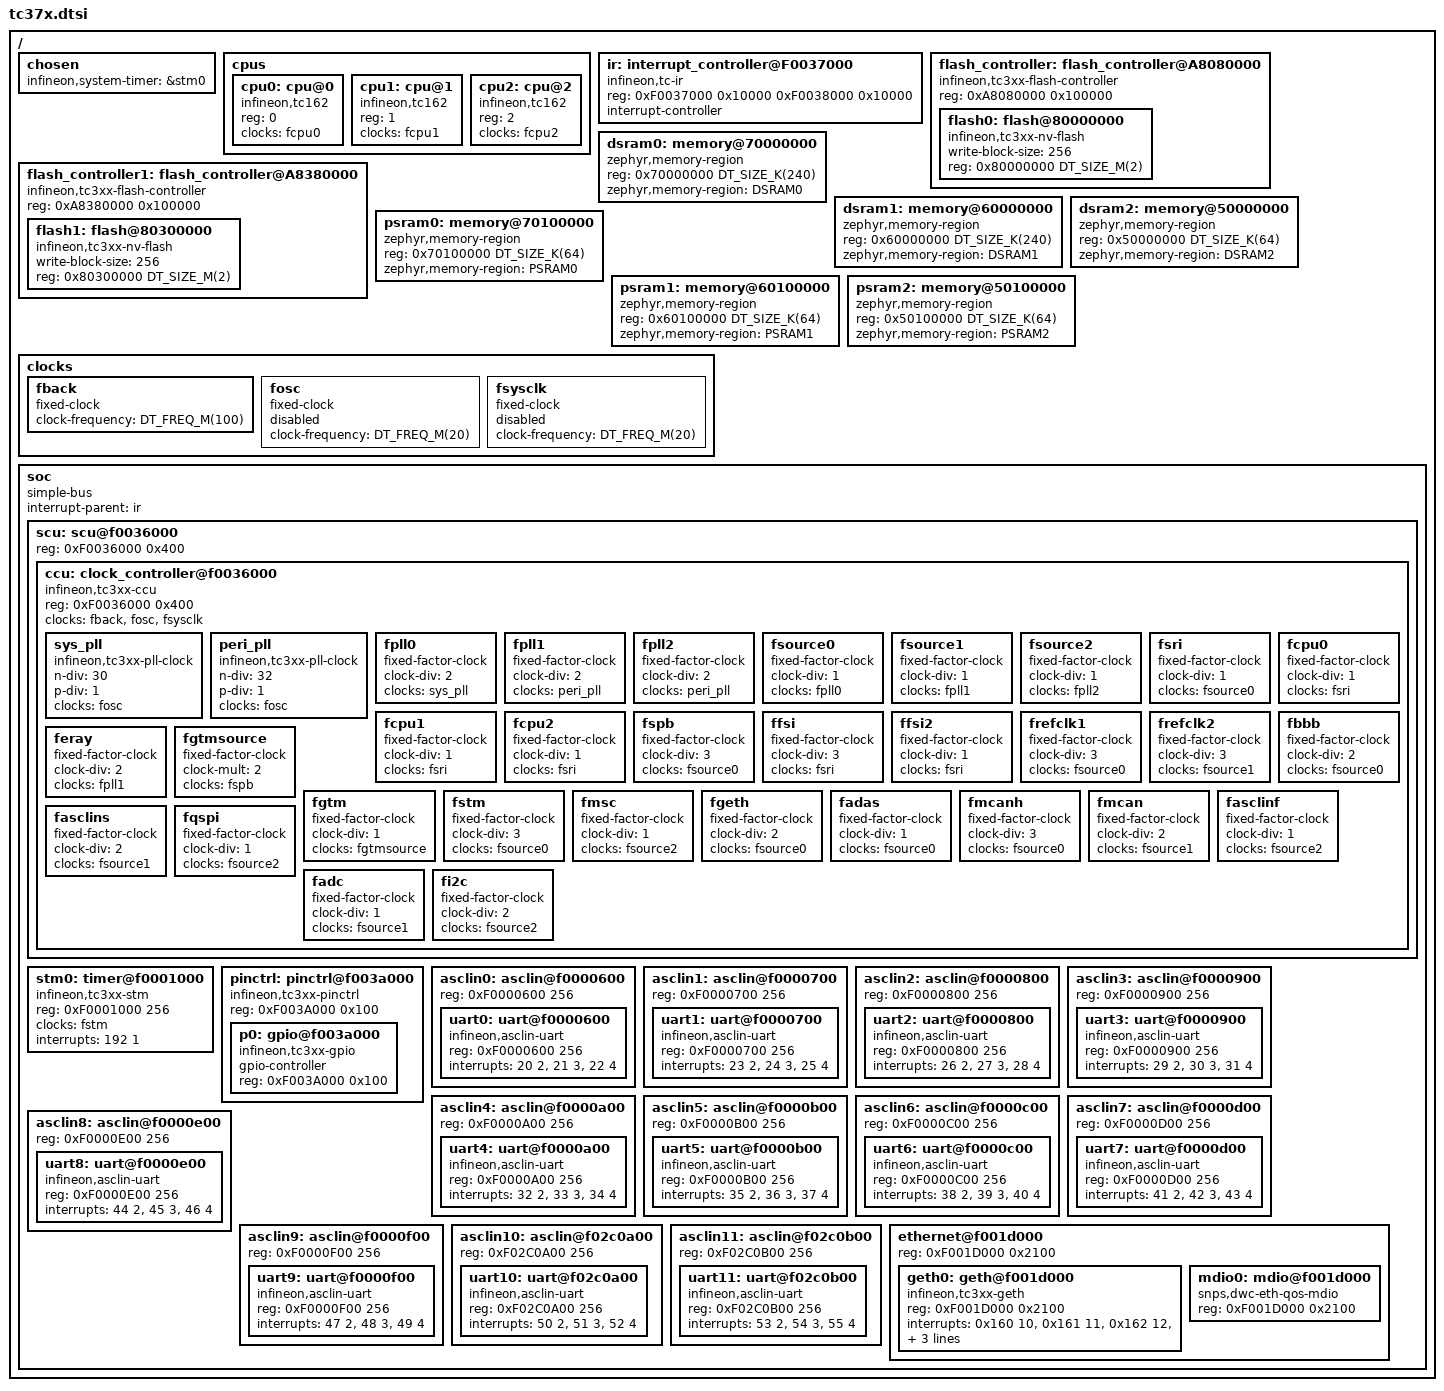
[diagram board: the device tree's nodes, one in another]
/*
 * Copyright (c) 2024 Infineon Technologies AG
 *
 * SPDX-License-Identifier: Apache-2.0
 */

#include <mem.h>
#include <freq.h>
#include <skeleton.dtsi>
#include <zephyr/dt-bindings/gpio/gpio.h>

/ {
	chosen {
		infineon,system-timer = &stm0;
	};

	cpus {
		#address-cells = <1>;
		#size-cells = <0>;

		cpu0: cpu@0 {
			device_type = "cpu";
			compatible = "infineon,tc162";
			reg = <0>;
			clocks = <&fcpu0>;
		};

        cpu1: cpu@1 {
			device_type = "cpu";
			compatible = "infineon,tc162";
			reg = <1>;
			clocks = <&fcpu1>;
		};
        cpu2: cpu@2 {
			device_type = "cpu";
			compatible = "infineon,tc162";
			reg = <2>;
			clocks = <&fcpu2>;
		};
	};

	ir: interrupt_controller@F0037000 {
		compatible = "infineon,tc-ir";
		reg = <0xF0037000 0x10000 0xF0038000 0x10000>;
		#interrupt-cells = <2>;
		interrupt-controller;
	};

	flash_controller: flash_controller@A8080000 {
		compatible = "infineon,tc3xx-flash-controller";
		#address-cells = <1>;
		#size-cells = <1>;
		reg = <0xA8080000 0x100000>;
		flash0: flash@80000000 {
			compatible = "infineon,tc3xx-nv-flash","soc-nv-flash";
			write-block-size = <256>;
			reg = <0x80000000 DT_SIZE_M(2)>;
		};
	};

    flash_controller1: flash_controller@A8380000 {
		compatible = "infineon,tc3xx-flash-controller";
		reg = <0xA8380000 0x100000>;
		#address-cells = <1>;
		#size-cells = <1>;
		flash1: flash@80300000 {
			compatible = "infineon,tc3xx-nv-flash","soc-nv-flash";
			write-block-size = <256>;
			reg = <0x80300000 DT_SIZE_M(2)>;
		};
	};

	dsram0: memory@70000000 {
		compatible = "zephyr,memory-region","mmio-sram";
		reg = <0x70000000 DT_SIZE_K(240)>;
		zephyr,memory-region = "DSRAM0";
	};

	dsram1: memory@60000000 {
		compatible = "zephyr,memory-region","mmio-sram";
		reg = <0x60000000 DT_SIZE_K(240)>;
		zephyr,memory-region = "DSRAM1";
	};

	dsram2: memory@50000000 {
		compatible = "zephyr,memory-region","mmio-sram";
		reg = <0x50000000 DT_SIZE_K(64)>;
		zephyr,memory-region = "DSRAM2";
	};

	psram0: memory@70100000 {
		compatible = "zephyr,memory-region","mmio-sram";
		reg = <0x70100000 DT_SIZE_K(64)>;
		zephyr,memory-region = "PSRAM0";
	};

	psram1: memory@60100000 {
		compatible = "zephyr,memory-region","mmio-sram";
		reg = <0x60100000 DT_SIZE_K(64)>;
		zephyr,memory-region = "PSRAM1";
	};

	psram2: memory@50100000 {
		compatible = "zephyr,memory-region","mmio-sram";
		reg = <0x50100000 DT_SIZE_K(64)>;
		zephyr,memory-region = "PSRAM2";
	};

	clocks {
		fback: fback {
			#clock-cells = <0>;
			compatible = "fixed-clock";
			clock-frequency = <DT_FREQ_M(100)>;
			status = "okay";
		};

		fosc: fosc {
			#clock-cells = <0>;
			compatible = "fixed-clock";
			clock-frequency = <DT_FREQ_M(20)>;
			status = "disabled";
		};

		fsysclk: fsysclk {
			#clock-cells = <0>;
			compatible = "fixed-clock";
			clock-frequency = <DT_FREQ_M(20)>;
			status = "disabled";
		};
	};
	
	soc {
		#address-cells = <1>;
		#size-cells = <1>;
		interrupt-parent = <&ir>;
		compatible = "simple-bus";
		ranges;

		scu: scu@f0036000 {
			#address-cells = <1>;
			#size-cells = <1>;
			reg = <0xF0036000 0x400>;

			ccu: clock_controller@f0036000 {
				#clock-cells = <1>;
				compatible = "infineon,tc3xx-ccu";
				reg = <0xF0036000 0x400>;
				clocks = <&fback>, <&fosc>, <&fsysclk>;
				status = "okay";

				sys_pll: sys_pll {
					#clock-cells = <0>;
					compatible = "infineon,tc3xx-pll-clock";
					n-div = <30>;
					p-div = <1>;
					clocks = <&fosc>;
				};

				peri_pll: peri_pll {
					#clock-cells = <0>;
					compatible = "infineon,tc3xx-pll-clock";
					n-div = <32>;
					p-div = <1>;
					clocks = <&fosc>;
				};

				fpll0: fpll0 {
					#clock-cells = <0>;
					compatible = "fixed-factor-clock";
					clock-div = <2>;
					clocks = <&sys_pll>;
				};
				
				fpll1: fpll1 {
					#clock-cells = <0>;
					compatible = "fixed-factor-clock";
					clock-div = <2>;
					clocks = <&peri_pll>;
				};

				fpll2: fpll2 {
					#clock-cells = <0>;
					compatible = "fixed-factor-clock";
					clock-div = <2>;
					clocks = <&peri_pll>;
				};

				fsource0: fsource0 {
					#clock-cells = <0>;
					compatible = "fixed-factor-clock";
					clock-div = <1>;
					clocks = <&fpll0>;
					status = "okay";
				};

				fsource1: fsource1{
					#clock-cells = <0>;
					compatible = "fixed-factor-clock";
					clock-div = <1>;
					clocks = <&fpll1>;
					status = "okay";
				};

				fsource2: fsource2 {
					#clock-cells = <0>;
					compatible = "fixed-factor-clock";
					clock-div = <1>;
					clocks = <&fpll2>;
					status = "okay";
				};

				fsri: fsri {
					compatible = "fixed-factor-clock";
					clock-div = <1>;
					#clock-cells = <0>;
					clocks = <&fsource0>;
				};

				fcpu0: fcpu0 {
					compatible = "fixed-factor-clock";
					clock-div = <1>;
					#clock-cells = <0>;
					clocks = <&fsri>;
				};

				fcpu1: fcpu1 {
					compatible = "fixed-factor-clock";
					clock-div = <1>;
					#clock-cells = <0>;
					clocks = <&fsri>;
				};

				fcpu2: fcpu2 {
					compatible = "fixed-factor-clock";
					clock-div = <1>;
					#clock-cells = <0>;
					clocks = <&fsri>;
				};

				fspb: fspb {
					compatible = "fixed-factor-clock";
					clock-div = <3>;
					#clock-cells = <0>;
					clocks = <&fsource0>;
				};

				ffsi: ffsi {
					compatible = "fixed-factor-clock";
					clock-div = <3>;
					#clock-cells = <0>;
					clocks = <&fsri>;
				};

				ffsi2: ffsi2 {
					compatible = "fixed-factor-clock";
					clock-div = <1>;
					#clock-cells = <0>;
					clocks = <&fsri>;
				};

				frefclk1: frefclk1 {
					compatible = "fixed-factor-clock";
					clock-div = <3>;
					#clock-cells = <0>;
					clocks = <&fsource0>;
				};

				frefclk2: frefclk2 {
					compatible = "fixed-factor-clock";
					clock-div = <3>;
					#clock-cells = <0>;
					clocks = <&fsource1>;
				};

				fbbb: fbbb {
					compatible = "fixed-factor-clock";
					clock-div = <2>;
					#clock-cells = <0>;
					clocks = <&fsource0>;
				};

				feray: feray {
					compatible = "fixed-factor-clock";
					clock-div = <2>;
					#clock-cells = <0>;
					clocks = <&fpll1>;
				};

				fgtmsource: fgtmsource {
					compatible = "fixed-factor-clock";
					clock-mult = <2>;
					#clock-cells = <0>;
					clocks = <&fspb>;	
				};

				fgtm: fgtm {
					compatible = "fixed-factor-clock";
					clock-div = <1>;
					#clock-cells = <0>;
					clocks = <&fgtmsource>;
				};
				
				fstm: fstm {
					compatible = "fixed-factor-clock";
					clock-div = <3>;
					#clock-cells = <0>;
					clocks = <&fsource0>;
				};

				fmsc: fmsc {
					compatible = "fixed-factor-clock";
					clock-div = <1>;
					#clock-cells = <0>;
					clocks = <&fsource2>;
				};

				fgeth: fgeth {
					compatible = "fixed-factor-clock";
					clock-div = <2>;
					#clock-cells = <0>;
					clocks = <&fsource0>;
				};

				/* Adas not available */
				fadas: fadas {
					compatible = "fixed-factor-clock";
					clock-div = <1>;
					#clock-cells = <0>;
					clocks = <&fsource0>;
				};

				fmcanh: fmcanh {
					compatible = "fixed-factor-clock";
					clock-div = <3>;
					#clock-cells = <0>;
					clocks = <&fsource0>;
				};

				fmcan: fmcan {
					compatible = "fixed-factor-clock";
					clock-div = <2>;
					#clock-cells = <0>;
					clocks = <&fsource1>;
				};

				fasclinf: fasclinf {
					compatible = "fixed-factor-clock";
					clock-div = <1>;
					#clock-cells = <0>;
					clocks = <&fsource2>;
				};

				fasclins: fasclins {
					compatible = "fixed-factor-clock";
					clock-div = <2>;
					#clock-cells = <0>;
					clocks = <&fsource1>;
				};

				fqspi: fqspi {
					compatible = "fixed-factor-clock";
					clock-div = <1>;
					#clock-cells = <0>;
					clocks = <&fsource2>;
				};

				fadc: fadc {
					compatible = "fixed-factor-clock";
					clock-div = <1>;
					#clock-cells = <0>;
					clocks = <&fsource1>;
				};

				fi2c: fi2c {
					compatible = "fixed-factor-clock";
					clock-div = <2>;
					#clock-cells = <0>;
					clocks = <&fsource2>;
				};
			};
		};

		stm0: timer@f0001000 {
			compatible = "infineon,tc3xx-stm";
			reg = <0xF0001000 256>;
			clocks = <&fstm>;
			interrupts = <192 1>;
		};

		pinctrl: pinctrl@f003a000 {
			compatible = "infineon,tc3xx-pinctrl";
			reg = <0xF003A000 0x100>;
			#address-cells = <1>;
			#size-cells = <1>;

			p0: gpio@f003a000 {
				compatible = "infineon,tc3xx-gpio";
				gpio-controller;
				#gpio-cells = <2>;
				reg = <0xF003A000 0x100>;
			};
		};
		
		asclin0: asclin@f0000600 {
			reg = <0xF0000600 256>;
			#address-cells = <1>;
			#size-cells = <1>;

			uart0: uart@f0000600 {
				compatible = "infineon,asclin-uart";
				reg = <0xF0000600 256>;
				interrupts = <20 2>, <21 3>, <22 4>;
				interrupt-names = "tx", "rx", "err";
			};
		};
				
		asclin1: asclin@f0000700 {
			reg = <0xF0000700 256>;
			#address-cells = <1>;
			#size-cells = <1>;

			uart1: uart@f0000700 {
				compatible = "infineon,asclin-uart";
				reg = <0xF0000700 256>;
				interrupts = <23 2>, <24 3>, <25 4>;
				interrupt-names = "tx", "rx", "err";
			};
		};
				
		asclin2: asclin@f0000800 {
			reg = <0xF0000800 256>;
			#address-cells = <1>;
			#size-cells = <1>;

			uart2: uart@f0000800 {
				compatible = "infineon,asclin-uart";
				reg = <0xF0000800 256>;
				interrupts = <26 2>, <27 3>, <28 4>;
				interrupt-names = "tx", "rx", "err";
			};
		};
				
		asclin3: asclin@f0000900 {
			reg = <0xF0000900 256>;
			#address-cells = <1>;
			#size-cells = <1>;

			uart3: uart@f0000900 {
				compatible = "infineon,asclin-uart";
				reg = <0xF0000900 256>;
				interrupts = <29 2>, <30 3>, <31 4>;
				interrupt-names = "tx", "rx", "err";
			};
		};

				
		asclin4: asclin@f0000a00 {
			reg = <0xF0000A00 256>;
			#address-cells = <1>;
			#size-cells = <1>;

			uart4: uart@f0000a00 {
				compatible = "infineon,asclin-uart";
				reg = <0xF0000A00 256>;
				interrupts = <32 2>, <33 3>, <34 4>;
				interrupt-names = "tx", "rx", "err";
			};
		};
			
		asclin5: asclin@f0000b00 {
			reg = <0xF0000B00 256>;
			#address-cells = <1>;
			#size-cells = <1>;

			uart5: uart@f0000b00 {
				compatible = "infineon,asclin-uart";
				reg = <0xF0000B00 256>;
				interrupts = <35 2>, <36 3>, <37 4>;
				interrupt-names = "tx", "rx", "err";
			};
		};
		
		asclin6: asclin@f0000c00 {
			reg = <0xF0000C00 256>;
			#address-cells = <1>;
			#size-cells = <1>;

			uart6: uart@f0000c00 {
				compatible = "infineon,asclin-uart";
				reg = <0xF0000C00 256>;
				interrupts = <38 2>, <39 3>, <40 4>;
				interrupt-names = "tx", "rx", "err";
			};
		};
				
		asclin7: asclin@f0000d00 {
			reg = <0xF0000D00 256>;
			#address-cells = <1>;
			#size-cells = <1>;

			uart7: uart@f0000d00 {
				compatible = "infineon,asclin-uart";
				reg = <0xF0000D00 256>;
				interrupts = <41 2>, <42 3>, <43 4>;
				interrupt-names = "tx", "rx", "err";
			};
		};
				
		asclin8: asclin@f0000e00 {
			reg = <0xF0000E00 256>;
			#address-cells = <1>;
			#size-cells = <1>;

			uart8: uart@f0000e00 {
				compatible = "infineon,asclin-uart";
				reg = <0xF0000E00 256>;
				interrupts = <44 2>, <45 3>, <46 4>;
				interrupt-names = "tx", "rx", "err";
			};
		};
				
		asclin9: asclin@f0000f00 {
			reg = <0xF0000F00 256>;
			#address-cells = <1>;
			#size-cells = <1>;

			uart9: uart@f0000f00 {
				compatible = "infineon,asclin-uart";
				reg = <0xF0000F00 256>;
				interrupts = <47 2>, <48 3>, <49 4>;
				interrupt-names = "tx", "rx", "err";
			};
		};
				
		asclin10: asclin@f02c0a00 {
			reg = <0xF02C0A00 256>;
			#address-cells = <1>;
			#size-cells = <1>;

			uart10: uart@f02c0a00 {
				compatible = "infineon,asclin-uart";
				reg = <0xF02C0A00 256>;
				interrupts = <50 2>, <51 3>, <52 4>;
				interrupt-names = "tx", "rx", "err";
			};
		};
				
		asclin11: asclin@f02c0b00 {
			reg = <0xF02C0B00 256>;
			#address-cells = <1>;
			#size-cells = <1>;

			uart11: uart@f02c0b00 {
				compatible = "infineon,asclin-uart";
				reg = <0xF02C0B00 256>;
				interrupts = <53 2>, <54 3>, <55 4>;
				interrupt-names = "tx", "rx", "err";
			};
		};

		ethernet@f001d000 {
			reg = <0xF001D000 0x2100>;
			#address-cells = <1>;
			#size-cells = <1>;
			geth0: geth@f001d000 {
				compatible = "infineon,tc3xx-geth", "snps,designware-ethernet";
				reg = <0xF001D000 0x2100>;
				interrupts = <0x160 10>, <0x161 11>, <0x162 12>, <0x163 13>, <0x164 14>, <0x165 15>, <0x166 16>, <0x167 17>, <0x168 18>, <0x169 19>;
				interrupt-names = "common", "pps", "tx0", "tx1", "tx2", "tx3", "rx0", "rx1", "rx2", "rx3";
				clocks = <&fgeth>;
			};

			mdio0: mdio@f001d000 {
				compatible = "snps,dwc-eth-qos-mdio";
				reg = <0xF001D000 0x2100>;
				#address-cells = <1>;
				#size-cells = <0>;
			};
		};
	};
};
